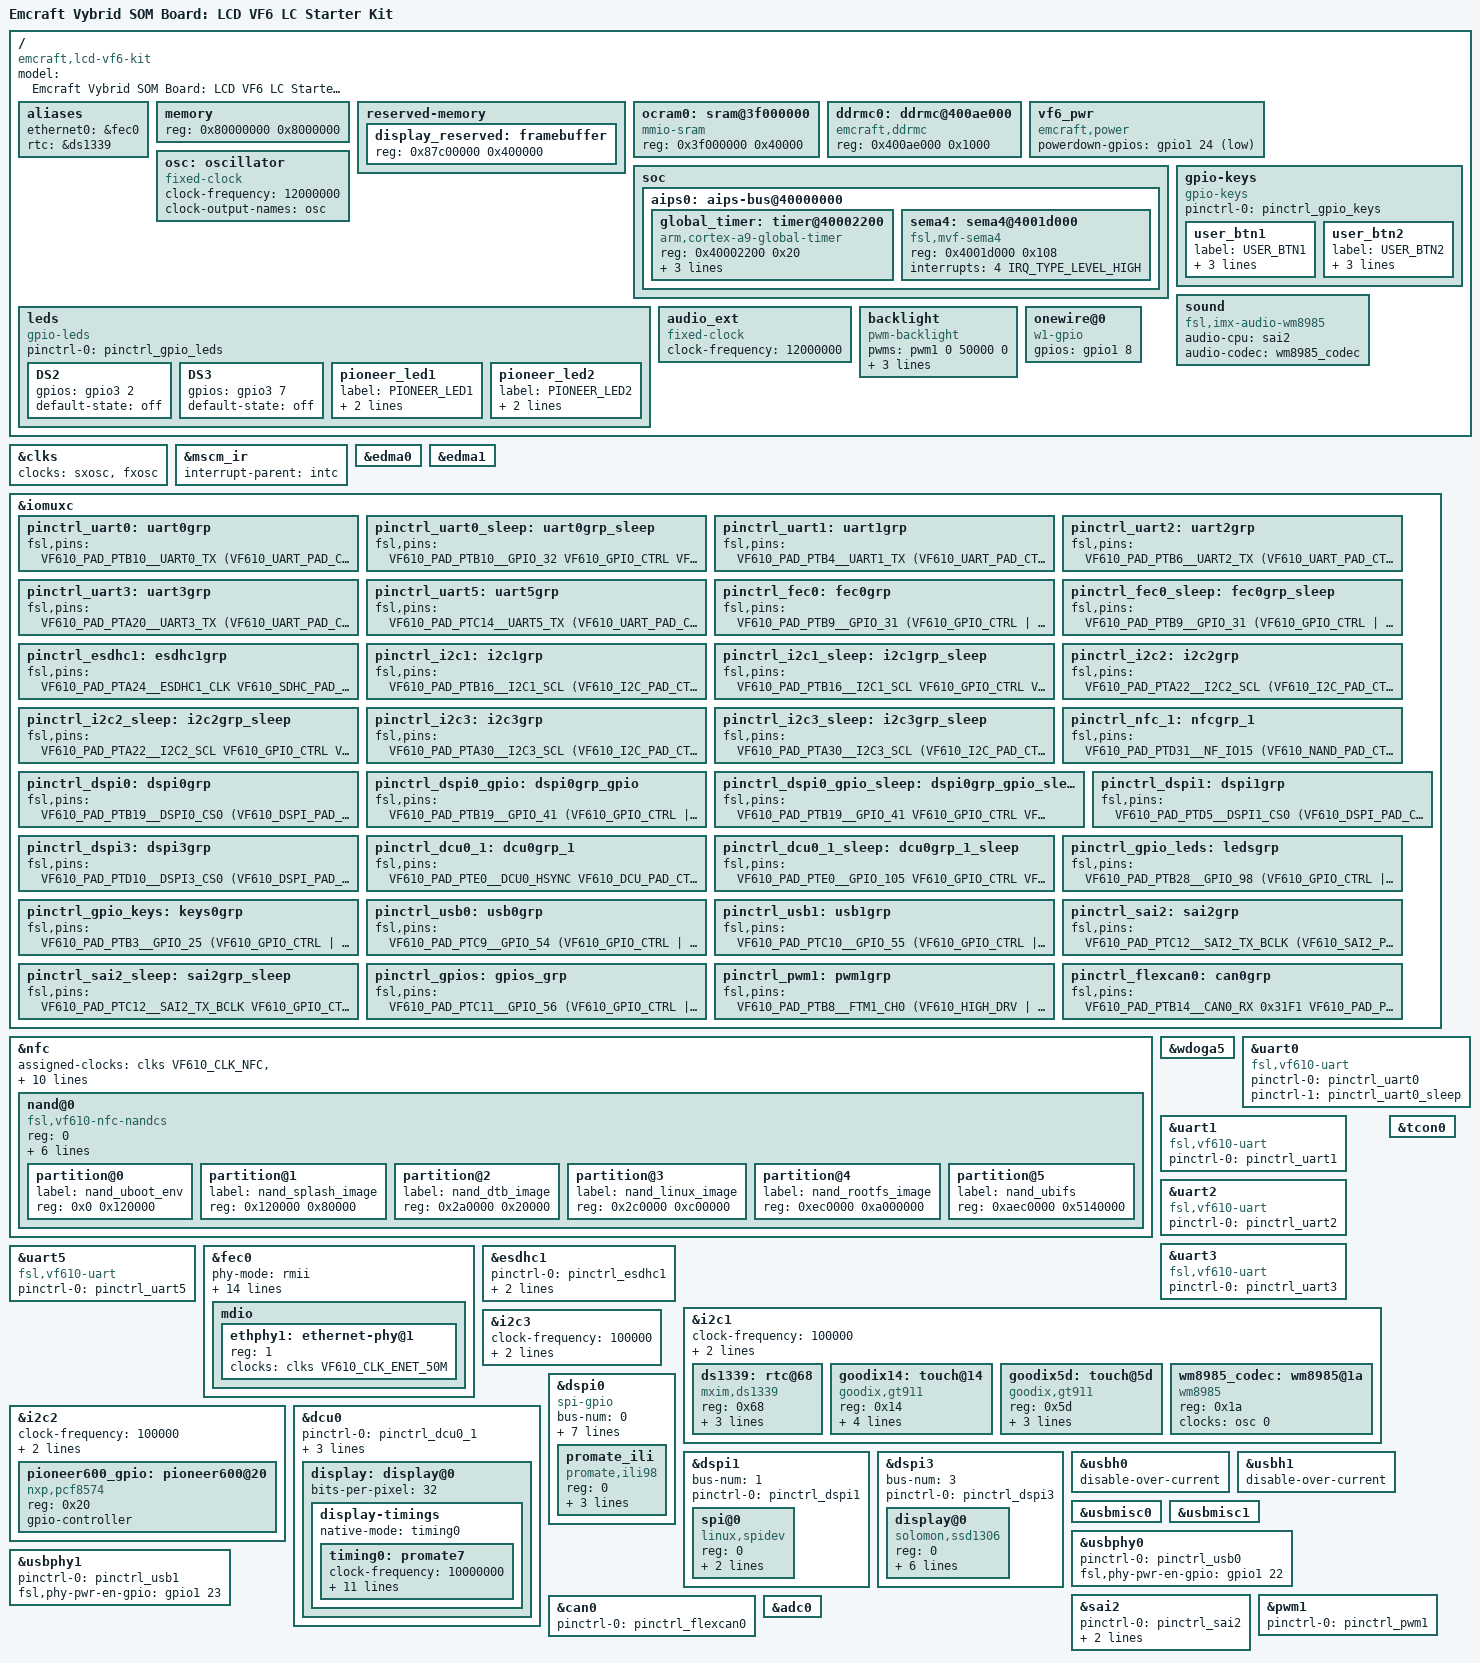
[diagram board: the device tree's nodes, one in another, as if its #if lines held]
/*
 * Copyright 2016 EmCraft Systems
 *
 * This program is free software; you can redistribute it and/or modify
 * it under the terms of the GNU General Public License as published by
 * the Free Software Foundation; either version 2 of the License, or
 * (at your option) any later version.
 */

/dts-v1/;
#include "vf610.dtsi"
#include <dt-bindings/input/input.h>

/*
 * Optionally, design of the Promate 4.3 LCD module used in the
 * Emcraft LCD VF6 SOM LC Starter Kit can make use of a Vybrid GPIO
 * in order to perform reset of the touch controller and LCD on the
 * LCD module. For such designs, enable the DEDICATED_TOUCH_RESET
 * macro in the code below (note that his macro is disabled by default
 * in the Emcraft BSP). Refer to the kit schematics (Page 5) for
 * additional details.
 */
#undef DEDICATED_TOUCH_RESET

/*
 * Pioneer 600 is an extension board for Raspberry Pi, which is used
 * to test compatibility with the Emcraft LCD VF6 SOM LC Starter Kit.
 */
#undef PIONEER_600

/ {
	model = "Emcraft Vybrid SOM Board: LCD VF6 LC Starter Kit";
	compatible = "emcraft,lcd-vf6-kit", "fsl,vf610";

	aliases {
		ethernet0 = &fec0;
		rtc = &ds1339;
	};

	memory {
		#address-cells = <1>;
		#size-cells = <1>;
		reg = <0x80000000 0x8000000>;
	};

	reserved-memory {
		#address-cells = <1>;
		#size-cells = <1>;
		ranges;

		display_reserved: framebuffer {
			reg = <0x87c00000 0x400000>;
		};
	};

	ocram0: sram@3f000000 {
		compatible = "mmio-sram";
		reg = <0x3f000000 0x40000>;
	};

	ddrmc0: ddrmc@400ae000 {
		compatible = "emcraft,ddrmc";
		reg = <0x400ae000 0x1000>;
	};

	vf6_pwr: vf6_pwr {
		compatible = "emcraft,power";
		powerdown-gpios = <&gpio1 24 GPIO_ACTIVE_LOW>;
	};

	osc: oscillator {
		compatible = "fixed-clock";
		#clock-cells = <1>;
		clock-frequency  = <12000000>;
		clock-output-names = "osc";
	};

	soc {

		aips0: aips-bus@40000000 {
			global_timer: timer@40002200 {
				compatible = "arm,cortex-a9-global-timer";
				reg = <0x40002200 0x20>;
				interrupts = <11 IRQ_TYPE_LEVEL_HIGH>;
				interrupt-parent = <&intc>;
				clocks = <&clks VF610_CLK_PLATFORM_BUS>;
			};

			sema4: sema4@4001d000 {
				compatible = "fsl,mvf-sema4";
				reg = <0x4001d000 0x108>;
				interrupts = <4 IRQ_TYPE_LEVEL_HIGH>;
			};
		};
	};

	leds {
		compatible = "gpio-leds";
		pinctrl-names = "default";
		pinctrl-0 = <&pinctrl_gpio_leds>;

		DS2 {
			gpios = <&gpio3 2 0>;
			default-state = "off";
		};

		DS3 {
			gpios = <&gpio3 7 0>;
			default-state = "off";
		};

#if defined(PIONEER_600)
		pioneer_led1 {
			label = "PIONEER_LED1";
			gpios = <&gpio2 23 GPIO_ACTIVE_HIGH>;
			default-state = "off";
		};

		pioneer_led2 {
			label = "PIONEER_LED2";
			gpios = <&pioneer600_gpio 4 GPIO_ACTIVE_LOW>;
			default-state = "off";
		};
#endif /* PIONEER_600 */
	};

	gpio-keys {
		compatible = "gpio-keys";
		pinctrl-names = "default";
		pinctrl-0 = <&pinctrl_gpio_keys>;

		user_btn1 {
			label = "USER_BTN1";
			gpios = <&gpio0 25 GPIO_ACTIVE_LOW>;
			gpio-key,wakeup;
			linux,code = <KEY_PROG1>;
		};

		user_btn2 {
			label = "USER_BTN2";
			gpios = <&gpio1 3 GPIO_ACTIVE_LOW>;
			gpio-key,wakeup;
			linux,code = <KEY_PROG2>;
		};
	};

	sound {
		compatible = "fsl,imx-audio-wm8985";

		audio-cpu = <&sai2>;

		audio-codec = <&wm8985_codec>;
	};

	audio_ext: audio_ext {
		compatible = "fixed-clock";
		#clock-cells = <0>;
		clock-frequency = <12000000>;
	};

	backlight: backlight {
		compatible = "pwm-backlight";
		pwms = <&pwm1 0 50000 0>;
		brightness-levels = <0 15 39 63 87 111 135 159 183 207 231 255>;
		default-brightness-level = <11>;
	};

#if defined(PIONEER_600)
	onewire@0 {
		compatible = "w1-gpio";
		gpios = <&gpio1 8 0>;
		status = "okay";
	};
#endif /* PIONEER_600 */
};

&clks {
	clocks = <&sxosc>, <&fxosc>;
	clock-names = "sxosc", "fxosc";
};

&mscm_ir {
	interrupt-parent = <&intc>;
};

&edma0 {
	status = "okay";
};

&edma1 {
	status = "okay";
};

&iomuxc {
	pinctrl_uart0: uart0grp {
		fsl,pins = <
		VF610_PAD_PTB10__UART0_TX	(VF610_UART_PAD_CTRL | PAD_CTL_OBE_ENABLE)
		VF610_PAD_PTB11__UART0_RX	(VF610_UART_PAD_CTRL | PAD_CTL_IBE_ENABLE)
		>;
	};
	pinctrl_uart0_sleep: uart0grp_sleep {
		fsl,pins = <
		VF610_PAD_PTB10__GPIO_32	VF610_GPIO_CTRL
		VF610_PAD_PTB11__UART0_RX	(VF610_UART_PAD_CTRL | PAD_CTL_IBE_ENABLE)
		>;
	};
	pinctrl_uart1: uart1grp {
		fsl,pins = <
		VF610_PAD_PTB4__UART1_TX	(VF610_UART_PAD_CTRL | PAD_CTL_OBE_ENABLE)
		VF610_PAD_PTB5__UART1_RX	(VF610_UART_PAD_CTRL | PAD_CTL_IBE_ENABLE)
		>;
	};
	pinctrl_uart2: uart2grp {
		fsl,pins = <
		VF610_PAD_PTB6__UART2_TX	(VF610_UART_PAD_CTRL | PAD_CTL_OBE_ENABLE)
		VF610_PAD_PTB7__UART2_RX	(VF610_UART_PAD_CTRL | PAD_CTL_IBE_ENABLE)
		>;
	};
	pinctrl_uart3: uart3grp {
		fsl,pins = <
		VF610_PAD_PTA20__UART3_TX	(VF610_UART_PAD_CTRL | PAD_CTL_OBE_ENABLE)
		VF610_PAD_PTA21__UART3_RX	(VF610_UART_PAD_CTRL | PAD_CTL_IBE_ENABLE)
		>;
	};
	pinctrl_uart5: uart5grp {
		fsl,pins = <
		VF610_PAD_PTC14__UART5_TX	(VF610_UART_PAD_CTRL | PAD_CTL_OBE_ENABLE)
		VF610_PAD_PTC15__UART5_RX	(VF610_UART_PAD_CTRL | PAD_CTL_IBE_ENABLE)
		>;
	};
	pinctrl_fec0: fec0grp {
		fsl,pins = <
		VF610_PAD_PTB9__GPIO_31		(VF610_GPIO_CTRL | PAD_CTL_OBE_ENABLE)
		VF610_PAD_PTA6__RMII_CLKOUT	(PAD_CTL_SPEED_LOW | PAD_CTL_SRE_SLOW | PAD_CTL_DSE_150ohm | PAD_CTL_OBE_ENABLE)
		VF610_PAD_PTC0__ENET_RMII0_MDC	(PAD_CTL_SPEED_LOW | PAD_CTL_SRE_SLOW | PAD_CTL_DSE_150ohm | PAD_CTL_OBE_ENABLE)
		VF610_PAD_PTC1__ENET_RMII0_MDIO	(PAD_CTL_SPEED_LOW | PAD_CTL_SRE_SLOW | PAD_CTL_DSE_150ohm | PAD_CTL_OBE_ENABLE | PAD_CTL_IBE_ENABLE)
		VF610_PAD_PTC2__ENET_RMII0_CRS	(PAD_CTL_SPEED_LOW | PAD_CTL_IBE_ENABLE)
		VF610_PAD_PTC3__ENET_RMII0_RXD1	(PAD_CTL_SPEED_LOW | PAD_CTL_IBE_ENABLE)
		VF610_PAD_PTC4__ENET_RMII0_RXD0	(PAD_CTL_SPEED_LOW | PAD_CTL_IBE_ENABLE)
		VF610_PAD_PTC5__ENET_RMII0_RXER	(PAD_CTL_SPEED_LOW | PAD_CTL_IBE_ENABLE)
		VF610_PAD_PTC6__ENET_RMII0_TXD1	(PAD_CTL_SPEED_LOW | PAD_CTL_SRE_SLOW | PAD_CTL_DSE_150ohm | PAD_CTL_OBE_ENABLE)
		VF610_PAD_PTC7__ENET_RMII0_TXD0	(PAD_CTL_SPEED_LOW | PAD_CTL_SRE_SLOW | PAD_CTL_DSE_150ohm | PAD_CTL_OBE_ENABLE)
		VF610_PAD_PTC8__ENET_RMII0_TXEN	(PAD_CTL_SPEED_LOW | PAD_CTL_SRE_SLOW | PAD_CTL_DSE_150ohm | PAD_CTL_OBE_ENABLE)
		>;
	};
	pinctrl_fec0_sleep: fec0grp_sleep {
		fsl,pins = <
		VF610_PAD_PTB9__GPIO_31		(VF610_GPIO_CTRL | PAD_CTL_OBE_ENABLE)
		VF610_PAD_PTA6__GPIO_0 		(VF610_GPIO_CTRL | PAD_CTL_OBE_ENABLE)
		VF610_PAD_PTC0__GPIO_45		(VF610_GPIO_CTRL | PAD_CTL_IBE_ENABLE)
		VF610_PAD_PTC1__GPIO_46		(VF610_GPIO_CTRL | PAD_CTL_IBE_ENABLE)
		VF610_PAD_PTC2__GPIO_47		(VF610_GPIO_CTRL | PAD_CTL_IBE_ENABLE)
		VF610_PAD_PTC3__GPIO_48		(VF610_GPIO_CTRL | PAD_CTL_IBE_ENABLE)
		VF610_PAD_PTC4__GPIO_49		(VF610_GPIO_CTRL | PAD_CTL_IBE_ENABLE)
		VF610_PAD_PTC5__GPIO_50		(VF610_GPIO_CTRL | PAD_CTL_IBE_ENABLE)
		VF610_PAD_PTC6__GPIO_51		(VF610_GPIO_CTRL | PAD_CTL_IBE_ENABLE)
		VF610_PAD_PTC7__GPIO_52		(VF610_GPIO_CTRL | PAD_CTL_IBE_ENABLE)
		VF610_PAD_PTC8__GPIO_53		(VF610_GPIO_CTRL | PAD_CTL_IBE_ENABLE)
		>;
	};
	pinctrl_esdhc1: esdhc1grp {
		fsl,pins = <
		VF610_PAD_PTA24__ESDHC1_CLK	VF610_SDHC_PAD_CTRL
		VF610_PAD_PTA25__ESDHC1_CMD	VF610_SDHC_PAD_CTRL
		VF610_PAD_PTA26__ESDHC1_DAT0	VF610_SDHC_PAD_CTRL
		VF610_PAD_PTA27__ESDHC1_DAT1	VF610_SDHC_PAD_CTRL
		VF610_PAD_PTA28__ESDHC1_DAT2	VF610_SDHC_PAD_CTRL
		VF610_PAD_PTA29__ESDHC1_DAT3	VF610_SDHC_PAD_CTRL
		VF610_PAD_PTC31__GPIO_104	(VF610_GPIO_CTRL | PAD_CTL_IBE_ENABLE)
		>;
	};
	pinctrl_i2c1: i2c1grp {
		fsl,pins = <
		VF610_PAD_PTB16__I2C1_SCL	(VF610_I2C_PAD_CTRL | PAD_CTL_OBE_IBE_ENABLE)
		VF610_PAD_PTB17__I2C1_SDA	(VF610_I2C_PAD_CTRL | PAD_CTL_OBE_IBE_ENABLE)

		/* TOUCH_INT */
		VF610_PAD_PTA19__GPIO_9		(PAD_CTL_DSE_25ohm | PAD_CTL_SPEED_HIGH | PAD_CTL_OBE_IBE_ENABLE)

	#if defined(DEDICATED_TOUCH_RESET)
		/* Touch Reset */
		VF610_PAD_PTA30__GPIO_20	(VF610_GPIO_CTRL | PAD_CTL_OBE_IBE_ENABLE)
	#endif

		/* WKUP_IRQ */
		VF610_PAD_PTB12__GPIO_34	(VF610_GPIO_CTRL | PAD_CTL_IBE_ENABLE)
		>;
	};
	pinctrl_i2c1_sleep: i2c1grp_sleep {
		fsl,pins = <
		VF610_PAD_PTB16__I2C1_SCL	VF610_GPIO_CTRL
		VF610_PAD_PTB17__I2C1_SDA	VF610_GPIO_CTRL

		/* TOUCH_INT */
		VF610_PAD_PTA19__GPIO_9		VF610_GPIO_CTRL

	#if defined(DEDICATED_TOUCH_RESET)
		/* Touch Reset */
		VF610_PAD_PTA30__GPIO_20	VF610_GPIO_CTRL
	#endif

		/* WKUP_IRQ */
		VF610_PAD_PTB12__GPIO_34	(VF610_GPIO_CTRL | PAD_CTL_IBE_ENABLE)
		>;
	};
	pinctrl_i2c2: i2c2grp {
		fsl,pins = <
		VF610_PAD_PTA22__I2C2_SCL	(VF610_I2C_PAD_CTRL | PAD_CTL_OBE_IBE_ENABLE)
		VF610_PAD_PTA23__I2C2_SDA	(VF610_I2C_PAD_CTRL | PAD_CTL_OBE_IBE_ENABLE)
		>;
	};
	pinctrl_i2c2_sleep: i2c2grp_sleep {
		fsl,pins = <
		VF610_PAD_PTA22__I2C2_SCL	VF610_GPIO_CTRL
		VF610_PAD_PTA23__I2C2_SDA	VF610_GPIO_CTRL
		>;
	};
	pinctrl_i2c3: i2c3grp {
		fsl,pins = <
		#if !defined(DEDICATED_TOUCH_RESET)
		VF610_PAD_PTA30__I2C3_SCL	(VF610_I2C_PAD_CTRL | PAD_CTL_OBE_IBE_ENABLE)
		#endif
		VF610_PAD_PTA31__I2C3_SDA	(VF610_I2C_PAD_CTRL | PAD_CTL_OBE_IBE_ENABLE)
		>;
	};
	pinctrl_i2c3_sleep: i2c3grp_sleep {
		fsl,pins = <
	#if !defined(DEDICATED_TOUCH_RESET)
		VF610_PAD_PTA30__I2C3_SCL	(VF610_I2C_PAD_CTRL | PAD_CTL_OBE_IBE_ENABLE)
	#endif
		VF610_PAD_PTA31__I2C3_SDA	VF610_GPIO_CTRL
		>;
	};
	pinctrl_nfc_1: nfcgrp_1 {
		fsl,pins = <
		VF610_PAD_PTD31__NF_IO15	(VF610_NAND_PAD_CTRL | PAD_CTL_PKE | PAD_CTL_PUE | PAD_CTL_OBE_IBE_ENABLE)
		VF610_PAD_PTD30__NF_IO14	(VF610_NAND_PAD_CTRL | PAD_CTL_PKE | PAD_CTL_PUE | PAD_CTL_OBE_IBE_ENABLE)
		VF610_PAD_PTD29__NF_IO13	(VF610_NAND_PAD_CTRL | PAD_CTL_PKE | PAD_CTL_PUE | PAD_CTL_OBE_IBE_ENABLE)
		VF610_PAD_PTD28__NF_IO12	(VF610_NAND_PAD_CTRL | PAD_CTL_PKE | PAD_CTL_PUE | PAD_CTL_OBE_IBE_ENABLE)
		VF610_PAD_PTD27__NF_IO11	(VF610_NAND_PAD_CTRL | PAD_CTL_PKE | PAD_CTL_PUE | PAD_CTL_OBE_IBE_ENABLE)
		VF610_PAD_PTD26__NF_IO10	(VF610_NAND_PAD_CTRL | PAD_CTL_PKE | PAD_CTL_PUE | PAD_CTL_OBE_IBE_ENABLE)
		VF610_PAD_PTD25__NF_IO9		(VF610_NAND_PAD_CTRL | PAD_CTL_PKE | PAD_CTL_PUE | PAD_CTL_OBE_IBE_ENABLE)
		VF610_PAD_PTD24__NF_IO8		(VF610_NAND_PAD_CTRL | PAD_CTL_PKE | PAD_CTL_PUE | PAD_CTL_OBE_IBE_ENABLE)
		VF610_PAD_PTD23__NF_IO7		(VF610_NAND_PAD_CTRL | PAD_CTL_PKE | PAD_CTL_PUE | PAD_CTL_OBE_IBE_ENABLE)
		VF610_PAD_PTD22__NF_IO6		(VF610_NAND_PAD_CTRL | PAD_CTL_PKE | PAD_CTL_PUE | PAD_CTL_OBE_IBE_ENABLE)
		VF610_PAD_PTD21__NF_IO5		(VF610_NAND_PAD_CTRL | PAD_CTL_PKE | PAD_CTL_PUE | PAD_CTL_OBE_IBE_ENABLE)
		VF610_PAD_PTD20__NF_IO4		(VF610_NAND_PAD_CTRL | PAD_CTL_PKE | PAD_CTL_PUE | PAD_CTL_OBE_IBE_ENABLE)
		VF610_PAD_PTD19__NF_IO3		(VF610_NAND_PAD_CTRL | PAD_CTL_PKE | PAD_CTL_PUE | PAD_CTL_OBE_IBE_ENABLE)
		VF610_PAD_PTD18__NF_IO2		(VF610_NAND_PAD_CTRL | PAD_CTL_PKE | PAD_CTL_PUE | PAD_CTL_OBE_IBE_ENABLE)
		VF610_PAD_PTD17__NF_IO1		(VF610_NAND_PAD_CTRL | PAD_CTL_PKE | PAD_CTL_PUE | PAD_CTL_OBE_IBE_ENABLE)
		VF610_PAD_PTD16__NF_IO0		(VF610_NAND_PAD_CTRL | PAD_CTL_PKE | PAD_CTL_PUE | PAD_CTL_OBE_IBE_ENABLE)
		VF610_PAD_PTC26__NF_RB_B	(VF610_NAND_PAD_CTRL | PAD_CTL_PKE | PAD_CTL_PUE | PAD_CTL_IBE_ENABLE)
		VF610_PAD_PTB24__NF_WE_B	(VF610_NAND_PAD_CTRL | PAD_CTL_OBE_ENABLE)
		VF610_PAD_PTB25__NF_CE0_B	(VF610_NAND_PAD_CTRL | PAD_CTL_OBE_ENABLE)
		VF610_PAD_PTB27__NF_RE_B	(VF610_NAND_PAD_CTRL | PAD_CTL_OBE_ENABLE)
		VF610_PAD_PTC27__NF_ALE		(VF610_NAND_PAD_CTRL | PAD_CTL_OBE_ENABLE)
		VF610_PAD_PTC28__NF_CLE		(VF610_NAND_PAD_CTRL | PAD_CTL_OBE_ENABLE)
		>;
	};
	pinctrl_dspi0: dspi0grp {
		fsl,pins = <
		VF610_PAD_PTB19__DSPI0_CS0	(VF610_DSPI_PAD_CTRL | PAD_CTL_OBE_ENABLE)
		VF610_PAD_PTB20__DSPI0_SIN	(VF610_DSPI_PAD_CTRL | PAD_CTL_IBE_ENABLE)
		VF610_PAD_PTB21__DSPI0_SOUT	(VF610_DSPI_PAD_CTRL | PAD_CTL_OBE_ENABLE)
		VF610_PAD_PTB22__DSPI0_SCK	(VF610_DSPI_PAD_CTRL | PAD_CTL_OBE_ENABLE)
		>;
	};
	pinctrl_dspi0_gpio: dspi0grp_gpio {
		fsl,pins = <
		VF610_PAD_PTB19__GPIO_41	(VF610_GPIO_CTRL | PAD_CTL_OBE_ENABLE)
		VF610_PAD_PTB20__GPIO_42	(VF610_GPIO_CTRL | PAD_CTL_IBE_ENABLE)
		VF610_PAD_PTB21__GPIO_43	(VF610_GPIO_CTRL | PAD_CTL_OBE_ENABLE)
		VF610_PAD_PTB22__GPIO_44	(VF610_GPIO_CTRL | PAD_CTL_OBE_ENABLE)
		>;
	};
	pinctrl_dspi0_gpio_sleep: dspi0grp_gpio_sleep {
		fsl,pins = <
		VF610_PAD_PTB19__GPIO_41	VF610_GPIO_CTRL
		VF610_PAD_PTB20__GPIO_42	VF610_GPIO_CTRL
		VF610_PAD_PTB21__GPIO_43	VF610_GPIO_CTRL
		VF610_PAD_PTB22__GPIO_44	VF610_GPIO_CTRL
		>;
	};
#if !defined(PIONEER_600)
	pinctrl_dspi1: dspi1grp {
		fsl,pins = <
		VF610_PAD_PTD5__DSPI1_CS0	(VF610_DSPI_PAD_CTRL | PAD_CTL_OBE_IBE_ENABLE)
		VF610_PAD_PTD4__DSPI1_CS1	(VF610_DSPI_PAD_CTRL | PAD_CTL_OBE_IBE_ENABLE)
		VF610_PAD_PTD3__DSPI1_CS2	(VF610_DSPI_PAD_CTRL | PAD_CTL_OBE_IBE_ENABLE)
		VF610_PAD_PTD2__DSPI1_CS3	(VF610_DSPI_PAD_CTRL | PAD_CTL_OBE_IBE_ENABLE)
		VF610_PAD_PTD6__DSPI1_SIN	(VF610_DSPI_PAD_CTRL | PAD_CTL_IBE_ENABLE)
		VF610_PAD_PTD7__DSPI1_SOUT	(VF610_DSPI_PAD_CTRL | PAD_CTL_OBE_ENABLE)
		VF610_PAD_PTD8__DSPI1_SCK	(VF610_DSPI_PAD_CTRL | PAD_CTL_OBE_IBE_ENABLE)
		>;
	};
#endif /* !PIONEER_600 */
	pinctrl_dspi3: dspi3grp {
		fsl,pins = <
		VF610_PAD_PTD10__DSPI3_CS0	(VF610_DSPI_PAD_CTRL | PAD_CTL_OBE_IBE_ENABLE)
		VF610_PAD_PTD9__DSPI3_CS1	(VF610_DSPI_PAD_CTRL | PAD_CTL_OBE_IBE_ENABLE)
		VF610_PAD_PTD11__DSPI3_SIN	(VF610_DSPI_PAD_CTRL | PAD_CTL_IBE_ENABLE)
		VF610_PAD_PTD12__DSPI3_SOUT	(VF610_DSPI_PAD_CTRL | PAD_CTL_OBE_ENABLE)
		VF610_PAD_PTD13__DSPI3_SCK	(VF610_DSPI_PAD_CTRL | PAD_CTL_OBE_IBE_ENABLE)
		>;
	};
	pinctrl_dcu0_1: dcu0grp_1 {
		fsl,pins = <
		VF610_PAD_PTE0__DCU0_HSYNC	VF610_DCU_PAD_CTRL
		VF610_PAD_PTE1__DCU0_VSYNC	VF610_DCU_PAD_CTRL
		VF610_PAD_PTE2__DCU0_PCLK	VF610_DCU_PAD_CTRL
		VF610_PAD_PTE4__DCU0_DE		VF610_DCU_PAD_CTRL
		VF610_PAD_PTE5__DCU0_R0		VF610_DCU_PAD_CTRL
		VF610_PAD_PTE6__DCU0_R1		VF610_DCU_PAD_CTRL
		VF610_PAD_PTE7__DCU0_R2		VF610_DCU_PAD_CTRL
		VF610_PAD_PTE8__DCU0_R3		VF610_DCU_PAD_CTRL
		VF610_PAD_PTE9__DCU0_R4		VF610_DCU_PAD_CTRL
		VF610_PAD_PTE10__DCU0_R5	VF610_DCU_PAD_CTRL
		VF610_PAD_PTE11__DCU0_R6	VF610_DCU_PAD_CTRL
		VF610_PAD_PTE12__DCU0_R7	VF610_DCU_PAD_CTRL
		VF610_PAD_PTE13__DCU0_G0	VF610_DCU_PAD_CTRL
		VF610_PAD_PTE14__DCU0_G1	VF610_DCU_PAD_CTRL
		VF610_PAD_PTE15__DCU0_G2	VF610_DCU_PAD_CTRL
		VF610_PAD_PTE16__DCU0_G3	VF610_DCU_PAD_CTRL
		VF610_PAD_PTE17__DCU0_G4	VF610_DCU_PAD_CTRL
		VF610_PAD_PTE18__DCU0_G5	VF610_DCU_PAD_CTRL
		VF610_PAD_PTE19__DCU0_G6	VF610_DCU_PAD_CTRL
		VF610_PAD_PTE20__DCU0_G7	VF610_DCU_PAD_CTRL
		VF610_PAD_PTE21__DCU0_B0	VF610_DCU_PAD_CTRL
		VF610_PAD_PTE22__DCU0_B1	VF610_DCU_PAD_CTRL
		VF610_PAD_PTE23__DCU0_B2	VF610_DCU_PAD_CTRL
		VF610_PAD_PTE24__DCU0_B3	VF610_DCU_PAD_CTRL
		VF610_PAD_PTE25__DCU0_B4	VF610_DCU_PAD_CTRL
		VF610_PAD_PTE26__DCU0_B5	VF610_DCU_PAD_CTRL
		VF610_PAD_PTE27__DCU0_B6	VF610_DCU_PAD_CTRL
		VF610_PAD_PTE28__DCU0_B7	VF610_DCU_PAD_CTRL
		>;
	};
	pinctrl_dcu0_1_sleep: dcu0grp_1_sleep {
		fsl,pins = <
		VF610_PAD_PTE0__GPIO_105	VF610_GPIO_CTRL
		VF610_PAD_PTE1__GPIO_106	VF610_GPIO_CTRL
		VF610_PAD_PTE2__GPIO_107	VF610_GPIO_CTRL
		VF610_PAD_PTE4__GPIO_109	VF610_GPIO_CTRL
		VF610_PAD_PTE7__GPIO_112	VF610_GPIO_CTRL
		VF610_PAD_PTE5__GPIO_110	VF610_GPIO_CTRL
		VF610_PAD_PTE6__GPIO_111	VF610_GPIO_CTRL
		VF610_PAD_PTE8__GPIO_113	VF610_GPIO_CTRL
		VF610_PAD_PTE9__GPIO_114	VF610_GPIO_CTRL
		VF610_PAD_PTE10__GPIO_115	VF610_GPIO_CTRL
		VF610_PAD_PTE11__GPIO_116	VF610_GPIO_CTRL
		VF610_PAD_PTE12__GPIO_117	VF610_GPIO_CTRL
		VF610_PAD_PTE13__GPIO_118	VF610_GPIO_CTRL
		VF610_PAD_PTE14__GPIO_119	VF610_GPIO_CTRL
		VF610_PAD_PTE15__GPIO_120	VF610_GPIO_CTRL
		VF610_PAD_PTE16__GPIO_121	VF610_GPIO_CTRL
		VF610_PAD_PTE17__GPIO_122	VF610_GPIO_CTRL
		VF610_PAD_PTE18__GPIO_123	VF610_GPIO_CTRL
		VF610_PAD_PTE19__GPIO_124	VF610_GPIO_CTRL
		VF610_PAD_PTE20__GPIO_125	VF610_GPIO_CTRL
		VF610_PAD_PTE21__GPIO_126	VF610_GPIO_CTRL
		VF610_PAD_PTE22__GPIO_127	VF610_GPIO_CTRL
		VF610_PAD_PTE23__GPIO_128	VF610_GPIO_CTRL
		VF610_PAD_PTE24__GPIO_129	VF610_GPIO_CTRL
		VF610_PAD_PTE25__GPIO_130	VF610_GPIO_CTRL
		VF610_PAD_PTE26__GPIO_131	VF610_GPIO_CTRL
		VF610_PAD_PTE27__GPIO_132	VF610_GPIO_CTRL
		VF610_PAD_PTE28__GPIO_133	VF610_GPIO_CTRL
		>;
	};
	pinctrl_gpio_leds: ledsgrp {
		fsl,pins = <
		VF610_PAD_PTB28__GPIO_98	(VF610_GPIO_CTRL | PAD_CTL_OBE_ENABLE)
		VF610_PAD_PTC30__GPIO_103	(VF610_GPIO_CTRL | PAD_CTL_OBE_ENABLE)
		>;
	};
	pinctrl_gpio_keys: keys0grp {
		fsl,pins = <
		VF610_PAD_PTB3__GPIO_25		(VF610_GPIO_CTRL | PAD_CTL_IBE_ENABLE)
		VF610_PAD_PTB13__GPIO_35	(VF610_GPIO_CTRL | PAD_CTL_IBE_ENABLE)
		>;
	};
	pinctrl_usb0: usb0grp {
		fsl,pins = <
		VF610_PAD_PTC9__GPIO_54		(VF610_GPIO_CTRL | PAD_CTL_OBE_ENABLE)
		>;
	};
	pinctrl_usb1: usb1grp {
		fsl,pins = <
		VF610_PAD_PTC10__GPIO_55	(VF610_GPIO_CTRL | PAD_CTL_OBE_ENABLE)
		>;
	};
	pinctrl_sai2: sai2grp {
		fsl,pins = <
		VF610_PAD_PTC12__SAI2_TX_BCLK	(VF610_SAI2_PAD_CTRL | PAD_CTL_IBE_ENABLE)
		VF610_PAD_PTB1__SAI2_RX_DATA	(VF610_SAI2_PAD_CTRL | PAD_CTL_OBE_ENABLE)
		VF610_PAD_PTA18__SAI2_TX_DATA	(VF610_SAI2_PAD_CTRL | PAD_CTL_IBE_ENABLE)
		VF610_PAD_PTC17__SAI2_TX_SYNC	(VF610_SAI2_PAD_CTRL | PAD_CTL_IBE_ENABLE)
		>;
	};
	pinctrl_sai2_sleep: sai2grp_sleep {
		fsl,pins = <
		VF610_PAD_PTC12__SAI2_TX_BCLK	VF610_GPIO_CTRL
		VF610_PAD_PTB1__SAI2_RX_DATA	VF610_GPIO_CTRL
		VF610_PAD_PTA18__SAI2_TX_DATA	VF610_GPIO_CTRL
		VF610_PAD_PTC17__SAI2_TX_SYNC	VF610_GPIO_CTRL
		>;
	};
	pinctrl_gpios: gpios_grp {
		fsl,pins = <
		/* nPOWERDOWN */
		VF610_PAD_PTC11__GPIO_56	(VF610_GPIO_CTRL | PAD_CTL_OBE_ENABLE)

		/* USB0_nFAULT */
		VF610_PAD_PTA16__GPIO_6		(VF610_GPIO_CTRL | PAD_CTL_IBE_ENABLE)

		/* USB1_nFAULT */
		VF610_PAD_PTB23__GPIO_93	(VF610_GPIO_CTRL | PAD_CTL_IBE_ENABLE)

		/* VCC3_P_FAULT (active low) */
		VF610_PAD_PTA7__GPIO_134	(VF610_GPIO_CTRL | PAD_CTL_IBE_ENABLE)

		/* VA_EN BUFF (LOW - powered from USB<->UART, HIGH - powered from 5V source) */
		VF610_PAD_PTC16__GPIO_61	(VF610_GPIO_CTRL | PAD_CTL_IBE_ENABLE)


		/* ID_SD (Raspberry Pi) */
		VF610_PAD_PTE3__GPIO_108	(VF610_GPIO_CTRL | PAD_CTL_OBE_IBE_ENABLE)

		/* ID_SC (Raspberry Pi) */
		VF610_PAD_PTA17__GPIO_7		(VF610_GPIO_CTRL | PAD_CTL_OBE_IBE_ENABLE)

		/* Free gpios for Raspberry Pi) */
		VF610_PAD_PTA12__GPIO_5		(VF610_GPIO_CTRL | PAD_CTL_OBE_IBE_ENABLE)
		VF610_PAD_PTB0__GPIO_22		(VF610_GPIO_CTRL | PAD_CTL_OBE_IBE_ENABLE)
		VF610_PAD_PTB2__GPIO_24		(VF610_GPIO_CTRL | PAD_CTL_OBE_IBE_ENABLE)
		VF610_PAD_PTB18__GPIO_40	(VF610_GPIO_CTRL | PAD_CTL_OBE_IBE_ENABLE)
		VF610_PAD_PTC29__GPIO_102	(VF610_GPIO_CTRL | PAD_CTL_OBE_IBE_ENABLE)
		VF610_PAD_PTC13__GPIO_58	(VF610_GPIO_CTRL | PAD_CTL_OBE_IBE_ENABLE)
		VF610_PAD_PTD0__GPIO_79		(VF610_GPIO_CTRL | PAD_CTL_OBE_IBE_ENABLE)
		VF610_PAD_PTD1__GPIO_80		(VF610_GPIO_CTRL | PAD_CTL_OBE_IBE_ENABLE)

#if defined(PIONEER_600)
		/* Pioneer 600 (Raspberry Pi) */
		VF610_PAD_PTD4__GPIO_83		(VF610_GPIO_CTRL | PAD_CTL_OBE_IBE_ENABLE)
		VF610_PAD_PTD7__GPIO_86		(VF610_GPIO_CTRL | PAD_CTL_OBE_IBE_ENABLE)
		VF610_PAD_PTD8__GPIO_87		(VF610_GPIO_CTRL | PAD_CTL_OBE_IBE_ENABLE)
#endif /* PIONEER_600 */
		>;
	};
	pinctrl_pwm1: pwm1grp {
		fsl,pins = <
		VF610_PAD_PTB8__FTM1_CH0	(VF610_HIGH_DRV | PAD_CTL_OBE_ENABLE)
		>;
	};
	pinctrl_flexcan0: can0grp {
		fsl,pins = <
		VF610_PAD_PTB14__CAN0_RX	0x31F1
		VF610_PAD_PTB15__CAN0_TX	0x31F2
		>;
	};
};

&nfc {
	assigned-clocks = <&clks VF610_CLK_NFC>, <&clks VF610_CLK_NFC_EN>,
			<&clks VF610_CLK_NFC_SEL>, <&clks VF610_CLK_NFC_PRE_DIV>,
			<&clks VF610_CLK_NFC_FRAC_DIV>, <&clks VF610_CLK_PLL3_PFD1>;
	assigned-clock-parents = <0>, <0>, <&clks VF610_CLK_PLL3_PFD1>, <0>, <0>, <0>;
	assigned-clock-rates = <0>, <0>, <0>, <480000000>, <40000000>, <480000000>;

	pinctrl-names = "default";
	pinctrl-0 = <&pinctrl_nfc_1>;
	status = "okay";

	nand@0 {
		compatible = "fsl,vf610-nfc-nandcs";
		reg = <0>;
		#address-cells = <1>;
		#size-cells = <1>;
		nand-bus-width = <16>;
		nand-ecc-mode = "hw";
		nand-ecc-strength = <24>;
		nand-ecc-step-size = <2048>;
		nand-on-flash-bbt;
		nand-use-read-cache;

		partition@0 {
			    label = "nand_uboot_env";
			    reg = <0x0 0x120000>;
		};

		partition@1 {
			    label = "nand_splash_image";
			    reg = <0x120000 0x80000>;
		};

		partition@2 {
			    label = "nand_dtb_image";
			    reg = <0x2a0000 0x20000>;
		};

		partition@3 {
			    label = "nand_linux_image";
			    reg = <0x2c0000 0xc00000>;
		};

		partition@4 {
			    label = "nand_rootfs_image";
			    reg = <0xec0000 0xa000000>;
		};

		partition@5 {
			    label = "nand_ubifs";
			    reg = <0xaec0000 0x5140000>;
		};

	};
};

&wdoga5 {
	status = "okay";
};

&uart0 {
	compatible = "fsl,vf610-uart";
	pinctrl-names = "default", "sleep";
	pinctrl-0 = <&pinctrl_uart0>;
	pinctrl-1 = <&pinctrl_uart0_sleep>;
	status = "okay";
};

&uart1 {
	compatible = "fsl,vf610-uart";
	pinctrl-names = "default";
	pinctrl-0 = <&pinctrl_uart1>;
	status = "okay";
};

&uart2 {
	compatible = "fsl,vf610-uart";
	pinctrl-names = "default";
	pinctrl-0 = <&pinctrl_uart2>;
	status = "okay";
};

&uart3 {
	compatible = "fsl,vf610-uart";
	pinctrl-names = "default";
	pinctrl-0 = <&pinctrl_uart3>;
	status = "okay";
};

&uart5 {
	compatible = "fsl,vf610-uart";
	pinctrl-names = "default";
	pinctrl-0 = <&pinctrl_uart5>;
	status = "okay";
};

&fec0 {
	phy-mode = "rmii";
	phy-handle = <&ethphy1>;
	pinctrl-names = "default", "sleep";
	pinctrl-0 = <&pinctrl_fec0>;
	pinctrl-1 = <&pinctrl_fec0_sleep>;
	status = "okay";

	clocks = <&clks VF610_CLK_ENET0>,
		<&clks VF610_CLK_PLL5_ENET>,
		<&clks VF610_CLK_ENET_SEL>,
		<&clks VF610_CLK_ENET>,
		<&clks VF610_CLK_ENET_50M>;
	clock-parents = <0>, <0>, <&clks VF610_CLK_ENET_50M>, <0>, <0>;
	clock-names = "ipg", "ahb", "enet_sel", "enet_out", "enet_50m";
	assigned-clocks = <&clks VF610_CLK_ENET_SEL>;
	assigned-clock-parents = <&clks VF610_CLK_ENET_50M>;

	osc-en-gpios = <&gpio0 31 GPIO_ACTIVE_LOW>;
	vf610,rmii-inverter-fix-gpios = <&gpio0 0 GPIO_ACTIVE_HIGH>;

	mdio {
		#address-cells = <1>;
		#size-cells = <0>;

		ethphy1: ethernet-phy@1 {
			reg = <1>;
			clocks = <&clks VF610_CLK_ENET_50M>;
			clock-names = "rmii-ref";
		};
	};
};

&esdhc1 {
	pinctrl-names = "default";
	pinctrl-0 = <&pinctrl_esdhc1>;
	bus-width = <4>;
	status = "okay";

	cd-gpios = <&gpio3 8 GPIO_ACTIVE_LOW>;
};

&i2c1 {
	clock-frequency = <100000>;
	pinctrl-names = "default", "sleep";
	pinctrl-0 = <&pinctrl_i2c1>;
	pinctrl-1 = <&pinctrl_i2c1_sleep>;
	status = "okay";

	ds1339: rtc@68 {
		compatible = "mxim,ds1339";
		reg = <0x68>;
		interrupt-parent = <&gpio1>;
		interrupts = <2 IRQ_TYPE_EDGE_BOTH>;
		irq-gpios = <&gpio1 2 GPIO_ACTIVE_HIGH>;
	};
	goodix14: touch@14 {
		compatible = "goodix,gt911";
		reg = <0x14>;
		interrupt-parent = <&gpio0>;
		interrupts = <9 IRQ_TYPE_EDGE_FALLING>;
		irq-gpios = <&gpio0 9 GPIO_ACTIVE_HIGH>;
		#if defined(DEDICATED_TOUCH_RESET)
		reset-gpios = <&gpio0 20 GPIO_ACTIVE_LOW>;
		#endif
	};
	#if !defined(DEDICATED_TOUCH_RESET)
	goodix5d: touch@5d {
		compatible = "goodix,gt911";
		reg = <0x5d>;
		interrupt-parent = <&gpio0>;
		interrupts = <9 IRQ_TYPE_EDGE_FALLING>;
		irq-gpios = <&gpio0 9 GPIO_ACTIVE_HIGH>;
	};
	#endif
	wm8985_codec: wm8985@1a {
		#sound-dai-cells = <0>;
		compatible = "wm8985";
		reg = <0x1a>;
		clocks = <&osc 0>;
	};
};

&i2c2 {
	clock-frequency = <100000>;
	pinctrl-names = "default", "sleep";
	pinctrl-0 = <&pinctrl_i2c2>;
	pinctrl-1 = <&pinctrl_i2c2_sleep>;
	status = "okay";

#if defined(PIONEER_600)
	pioneer600_gpio: pioneer600@20 {
		compatible = "nxp,pcf8574";
		reg = <0x20>;

		gpio-controller;
		#gpio-cells = <2>;
	};
#endif /* PIONEER_600 */
};

&i2c3 {
	clock-frequency = <100000>;
	pinctrl-names = "default", "sleep";
	pinctrl-0 = <&pinctrl_i2c3>;
	pinctrl-1 = <&pinctrl_i2c3_sleep>;
	status = "okay";
};

&tcon0 {
	status = "okay";
};

&dcu0 {
	pinctrl-names = "default", "sleep";
	pinctrl-0 = <&pinctrl_dcu0_1>;
	pinctrl-1 = <&pinctrl_dcu0_1_sleep>;
	display = <&display>;
	status = "okay";

	memory-region = <&display_reserved>;

	display: display@0 {
		bits-per-pixel = <32>;

		display-timings {
			native-mode = <&timing0>;
			timing0: promate7 {
				clock-frequency = <10000000>;
				hactive = <480>;
				vactive = <272>;
				hback-porch = <2>;
				hfront-porch = <2>;
				vback-porch = <2>;
				vfront-porch = <2>;
				hsync-len = <41>;
				vsync-len = <10>;
				hsync-active = <0>;
				vsync-active = <1>;
				pixelclk-active = <1>;
			};
		};
	};
};

&dspi0 {
	bus-num = <0>;
	pinctrl-names = "default", "sleep";
	pinctrl-0 = <&pinctrl_dspi0_gpio>;
	pinctrl-1 = <&pinctrl_dspi0_gpio_sleep>;
	compatible = "spi-gpio";
	status = "okay";

	cs-gpios	= <&gpio1 9 GPIO_ACTIVE_LOW>;
	gpio-miso	= <&gpio1 10 GPIO_ACTIVE_LOW>;
	gpio-mosi	= <&gpio1 11 GPIO_ACTIVE_LOW>;
	gpio-sck	= <&gpio1 12 GPIO_ACTIVE_LOW>;
	num-chipselects	= <1>;

	promate_ili: promate_ili {
		#address-cells = <1>;
		#size-cells = <1>;
		reg = <0>;
		spi-max-frequency = <200000>;
		spi-cpol;
		spi-cpha;

		compatible = "promate,ili98";
	};
};

#if !defined(PIONEER_600)
&dspi1 {
	bus-num = <1>;
	pinctrl-names = "default";
	pinctrl-0 = <&pinctrl_dspi1>;
	status = "okay";

	spi@0 {
		compatible = "linux,spidev";
		reg = <0>;
		spi-max-frequency = <20000000>;
		slave-mode;
	};
};
#endif /* !PIONEER_600 */

&dspi3 {
	bus-num = <3>;
	pinctrl-names = "default";
	pinctrl-0 = <&pinctrl_dspi3>;
	status = "okay";

#if defined(PIONEER_600)
	/* CS2 for Display */
	display@0 {
		compatible = "solomon,ssd1306";
		reg = <0>;
		spi-max-frequency = <20000000>;
		fsl,spi-sck-cs-delay = <70>;
		spi-cpol;
		spi-cpha;

		reset-gpios	= <&gpio2 22 GPIO_ACTIVE_HIGH>;
		dc-gpios	= <&gpio2 19 GPIO_ACTIVE_HIGH>;
	};
#else
	spi@0 {
		compatible = "linux,spidev";
		reg = <0>;
		spi-max-frequency = <20000000>;
		slave-mode;
	};
#endif /* PIONEER_600 */
};

&usbh0 {
	disable-over-current;
	status = "okay";
};

&usbh1 {
	disable-over-current;
	status = "okay";
};

&usbmisc0 {
	status = "okay";
};

&usbmisc1 {
	status = "okay";
};

&usbphy0 {
	pinctrl-names = "default";
	pinctrl-0 = <&pinctrl_usb0>;
	fsl,phy-pwr-en-gpio = <&gpio1 22 0>;
	status = "okay";
};

&usbphy1 {
	pinctrl-names = "default";
	pinctrl-0 = <&pinctrl_usb1>;
	fsl,phy-pwr-en-gpio = <&gpio1 23 0>;
	status = "okay";
};

&sai2 {
	#sound-dai-cells = <0>;
	pinctrl-names = "default", "sleep";
	pinctrl-0 = <&pinctrl_sai2>;
	pinctrl-1 = <&pinctrl_sai2_sleep>;
	status = "okay";

	clocks = <&clks VF610_CLK_SAI2>;
	clock-names = "bus";
};

&sema4 {
	status = "okay";
};

&pwm1 {
	status = "okay";
	pinctrl-names = "default";
	pinctrl-0 = <&pinctrl_pwm1>;
};

&can0 {
	pinctrl-names = "default";
	pinctrl-0 = <&pinctrl_flexcan0>;
	status = "okay";
};

&adc0 {
	status = "okay";
};
